# ms32c000axx register map
Vendor: MS; Series: MS32C; File version: 1.0.0
CPU: CM0+ r0p1, little endian, no MPU, no FPU, 4 interrupt priority bits
Registers are 32-bit, read-write, reset 0x0 unless marked. A register's access mark holds for its fields unless they carry their own. Offsets are from the block's base; [hi:lo] are bit positions; {n}, {i} and the like mark numbered series.

## PWR — Power control
Base 0x40007000
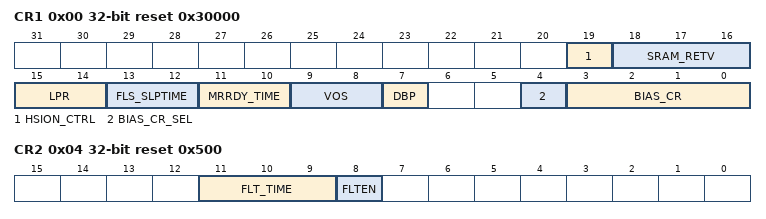
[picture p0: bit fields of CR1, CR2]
0x00 CR1 reset 0x30000 — Power control register 1
  [19] HSION_CTRL — HSI open time control
  [18:16] SRAM_RETV — SRAM retention voltage control
  [15:14] LPR — Low-power run
  [13:12] FLS_SLPTIME — Flash wait time after wakeup from the stop mode
  [11:10] MRRDY_TIME — Time selection wakeup from LP to VR
  [9:8] VOS — Voltage scaling range selection
  [7] DBP — Disable backup domain write protection
  [4] BIAS_CR_SEL — MR Bias current selection
  [3:0] BIAS_CR — MR Bias current
0x04 CR2 reset 0x500 — Power control register 2
  [11:9] FLT_TIME — Digital filter time configuration
  [8] FLTEN — Digital filter enable

## RCC — Reset and clock control
Base 0x40021000
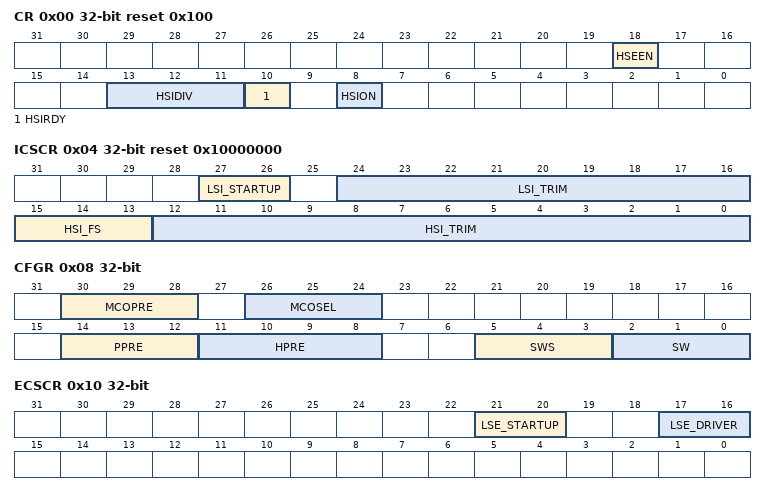
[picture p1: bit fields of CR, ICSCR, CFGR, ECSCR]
0x00 CR reset 0x100 — Clock control register
  [18] HSEEN
  [13:11] HSIDIV — HSI16 clock division factor
  [10] HSIRDY — HSI16 clock ready flag
  [8] HSION — HSI16 clock enable
0x04 ICSCR reset 0x10000000 — Internal clock sources calibration register
  [27:26] LSI_STARTUP — LSI startup time
  [24:16] LSI_TRIM — LSI clock trimming
  [15:13] HSI_FS — HSI frequency selection
  [12:0] HSI_TRIM — HSI clock trimming
0x08 CFGR — Clock configuration register
  [30:28] MCOPRE — Microcontroller clock output prescaler
  [26:24] MCOSEL — Microcontroller clock output
  [14:12] PPRE — APB prescaler
  [11:8] HPRE — AHB prescaler
  [5:3] SWS ro — System clock switch status
  [2:0] SW — System clock switch
0x10 ECSCR — External clock source control register
  [21:20] LSE_STARTUP, [17:16] LSE_DRIVER
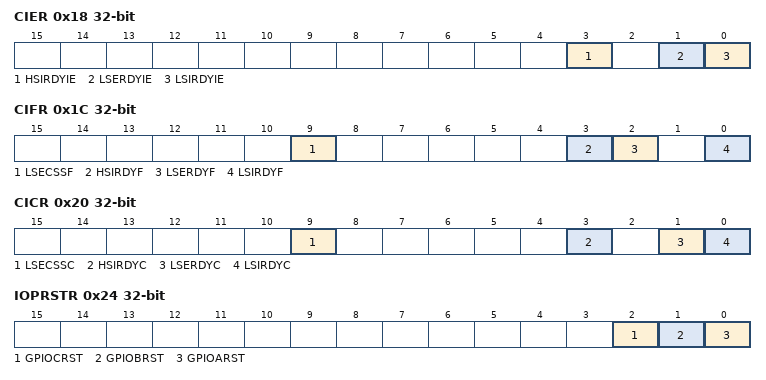
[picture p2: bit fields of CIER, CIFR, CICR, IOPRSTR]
0x18 CIER — Clock interrupt enable register
  [3] HSIRDYIE — HSI ready interrupt enable
  [1] LSERDYIE — LSE ready interrupt enable
  [0] LSIRDYIE — LSI ready interrupt enable
0x1C CIFR ro — Clock interrupt flag register
  [9] LSECSSF — LSE clock secure system interrupt flag
  [3] HSIRDYF — HSI ready interrupt flag
  [2] LSERDYF — LSE ready interrupt flag
  [0] LSIRDYF — LSI ready interrupt flag
0x20 CICR wo — Clock interrupt clear register
  [9] LSECSSC — LSE clock secure system interrupt flag clear
  [3] HSIRDYC — HSI ready interrupt clear
  [1] LSERDYC — LSE ready interrupt clear
  [0] LSIRDYC — LSI ready interrupt clear
0x24 IOPRSTR — GPIO reset register
  [2] GPIOCRST — I/O port C reset
  [1] GPIOBRST — I/O port B reset
  [0] GPIOARST — I/O port A reset
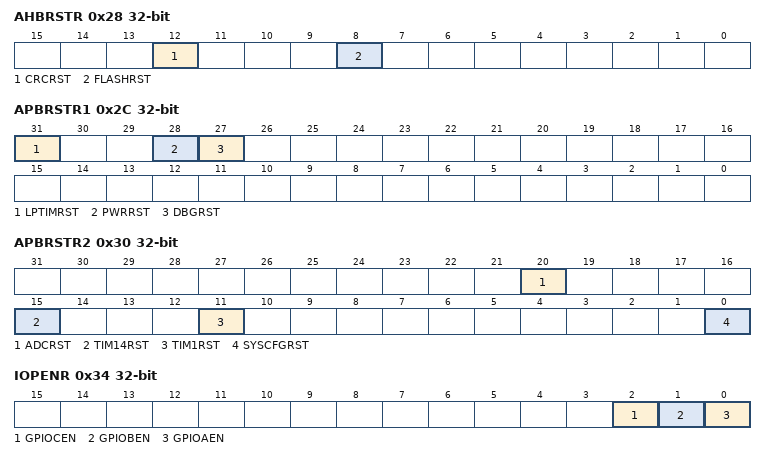
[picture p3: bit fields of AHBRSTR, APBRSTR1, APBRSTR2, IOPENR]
0x28 AHBRSTR — AHB peripheral reset register
  [12] CRCRST — CRC reset
  [8] FLASHRST — FLASH reset
0x2C APBRSTR1 — APB peripheral reset register 1
  [31] LPTIMRST — Low Power Timer reset
  [28] PWRRST — Power interface reset
  [27] DBGRST — Debug support reset
0x30 APBRSTR2 — APB peripheral reset register 2
  [20] ADCRST — ADC reset
  [15] TIM14RST — TIM14 reset
  [11] TIM1RST — TIM1 timer reset
  [0] SYSCFGRST — SYSCFG reset
0x34 IOPENR — GPIO clock enable register
  [2] GPIOCEN — I/O port C clock enable
  [1] GPIOBEN — I/O port B clock enable
  [0] GPIOAEN — I/O port A clock enable
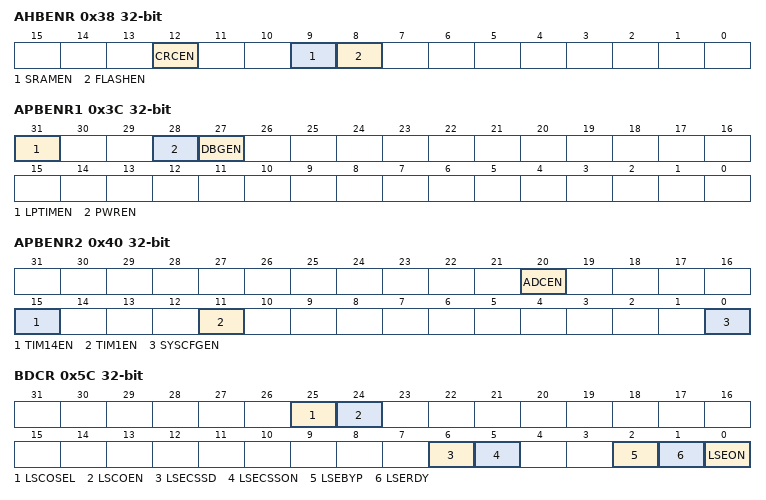
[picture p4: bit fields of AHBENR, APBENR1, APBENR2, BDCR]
0x38 AHBENR — AHB peripheral clock enable register
  [12] CRCEN — CRC clock enable
  [9] SRAMEN — SRAM memory interface clock enable
  [8] FLASHEN — Flash memory interface clock enable
0x3C APBENR1 — APB peripheral clock enable register 1
  [31] LPTIMEN — LPTIM clock enable
  [28] PWREN — Power interface clock enable
  [27] DBGEN — Debug support clock enable
0x40 APBENR2 — APB peripheral clock enable register 2
  [20] ADCEN — ADC clock enable
  [15] TIM14EN — TIM14 clock enable
  [11] TIM1EN — TIM1 timer clock enable
  [0] SYSCFGEN — SYSCFG and VREFBUF clock enable
0x54 CCIPR — Peripherals independent clock configuration register
  [19:18] LPTIM1SEL — LPTIM1 clock source selection
0x5C BDCR — RTC domain control register
  [25] LSCOSEL — Low-speed clock output selection
  [24] LSCOEN — Low-speed clock output (LSCO) enable
  [6] LSECSSD — LSE CSS detect
  [5] LSECSSON — LSE CSS enable
  [2] LSEBYP — LSE oscillator bypass
  [1] LSERDY — LSE oscillator ready
  [0] LSEON — LSE oscillator enable
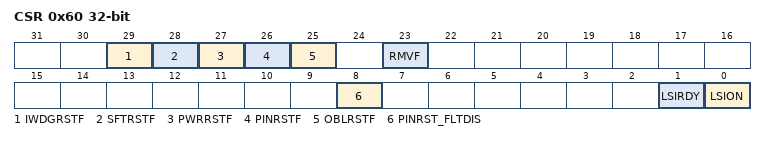
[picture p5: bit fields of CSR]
0x60 CSR — Control/status register
  [29] IWDGRSTF — Independent window watchdog reset flag
  [28] SFTRSTF — Software reset flag
  [27] PWRRSTF — BOR or POR/PDR flag
  [26] PINRSTF — Pin reset flag
  [25] OBLRSTF — Option byte loader reset flag
  [23] RMVF — Remove reset flags
  [8] PINRST_FLTDIS
  [1] LSIRDY — LSI oscillator ready
  [0] LSION — LSI oscillator enable

## SYSCFG — System configuration controller
Base 0x40010000
0x00 CFGR1 — SYSCFG configuration register 1
  [1:0] MEM_MODE — Memory mapping selection bits
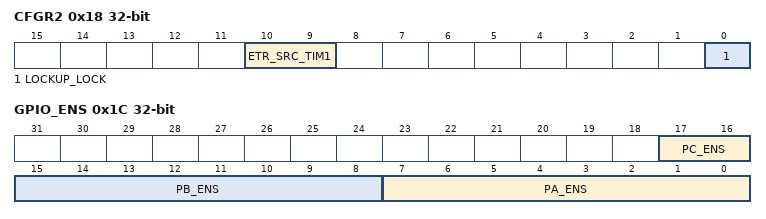
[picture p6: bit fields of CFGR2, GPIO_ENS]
0x18 CFGR2 — SYSCFG configuration register 2
  [10:9] ETR_SRC_TIM1 — TIM1 ETR source selection
  [0] LOCKUP_LOCK — Cortex-M0+ LOCKUP bit enable bit
0x1C GPIO_ENS
  [17:16] PC_ENS, [15:8] PB_ENS, [7:0] PA_ENS

## TIM1 — Advanced timer
Base 0x40012C00
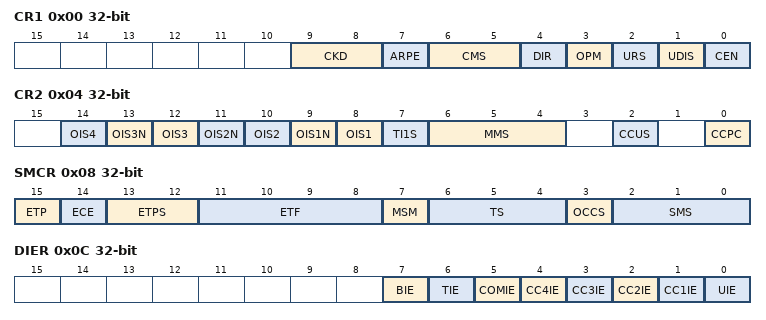
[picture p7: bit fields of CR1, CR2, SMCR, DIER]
0x00 CR1
  [9:8] CKD, [7] ARPE, [6:5] CMS, [4] DIR, [3] OPM, [2] URS, [1] UDIS, [0] CEN
0x04 CR2 (reset mask 0xF8)
  [2n+6] OIS{n} (n=1..4), [13] OIS3N, [11] OIS2N, [9] OIS1N, [7] TI1S, [6:4] MMS, [2] CCUS, [0] CCPC
0x08 SMCR (reset mask 0xFFF7)
  [15] ETP, [14] ECE, [13:12] ETPS, [11:8] ETF, [7] MSM, [6:4] TS, [3] OCCS, [2:0] SMS
0x0C DIER (reset mask 0x5F5F)
  [7] BIE, [6] TIE, [5] COMIE, [n] CC{n}IE (n=1..4), [0] UIE
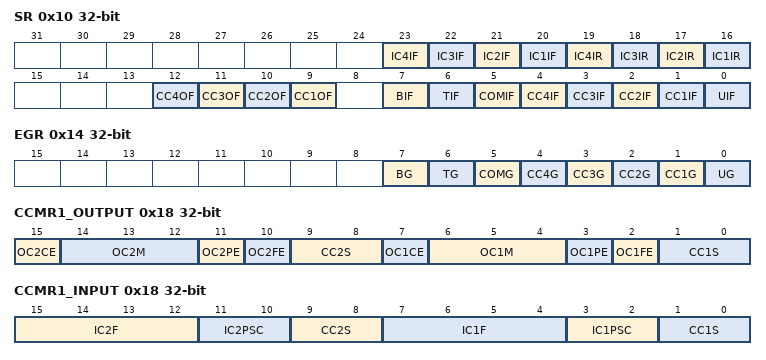
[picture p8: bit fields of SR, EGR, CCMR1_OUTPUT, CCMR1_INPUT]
0x10 SR (reset mask 0x1E5F)
  [23] IC4IF — desc IC3IF
  [22] IC3IF
  [21] IC2IF
  [20] IC1IF
  [19] IC4IR — desc IC3IR
  [18] IC3IR
  [17] IC2IR
  [16] IC1IR
  [n+8] CC{n}OF (n=1..4)
  [7] BIF
  [6] TIF
  [5] COMIF
  [n] CC{n}IF (n=1..4)
  [0] UIF
0x14 EGR wo (reset mask 0x5F)
  [7] BG
  [6] TG
  [5] COMG
  [4] CC4G
  [3] CC3G
  [2] CC2G
  [1] CC1G — Capture 1 Generation
  [0] UG
0x18 CCMR1_OUTPUT
  [15] OC2CE, [14:12] OC2M, [11] OC2PE, [10] OC2FE, [9:8] CC2S, [7] OC1CE, [6:4] OC1M, [3] OC1PE, [2] OC1FE, [1:0] CC1S
0x18 CCMR1_INPUT (alternate view of CCMR1_OUTPUT)
  [15:12] IC2F, [11:10] IC2PSC, [9:8] CC2S, [7:4] IC1F, [3:2] IC1PSC, [1:0] CC1S
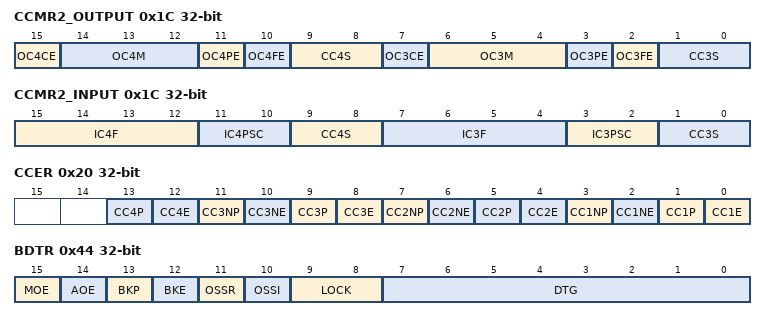
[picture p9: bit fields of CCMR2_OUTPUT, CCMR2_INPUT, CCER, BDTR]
0x1C CCMR2_OUTPUT
  [15] OC4CE, [14:12] OC4M, [11] OC4PE, [10] OC4FE, [9:8] CC4S, [7] OC3CE, [6:4] OC3M, [3] OC3PE, [2] OC3FE, [1:0] CC3S
0x1C CCMR2_INPUT (alternate view of CCMR2_OUTPUT)
  [15:12] IC4F, [11:10] IC4PSC, [9:8] CC4S, [7:4] IC3F, [3:2] IC3PSC, [1:0] CC3S
0x20 CCER (reset mask 0x3333)
  [4n-3] CC{n}P (n=1..4), [4n-4] CC{n}E (n=1..4), [11] CC3NP, [10] CC3NE, [7] CC2NP, [6] CC2NE, [3] CC1NP, [2] CC1NE
0x24 CNT
  [15:0] CNT
0x28 PSC
  [15:0] PSC
0x2C ARR reset 0xFFFF
  [15:0] ARR
0x30 RCR reset 0xFFFF
  [7:0] REP
{0x30+4i} CCR{i} (i=1..4)
  [15:0] CCR{i}
0x44 BDTR
  [15] MOE, [14] AOE, [13] BKP, [12] BKE, [11] OSSR, [10] OSSI, [9:8] LOCK, [7:0] DTG

## TIM14 — General purpose timer
Base 0x40002000
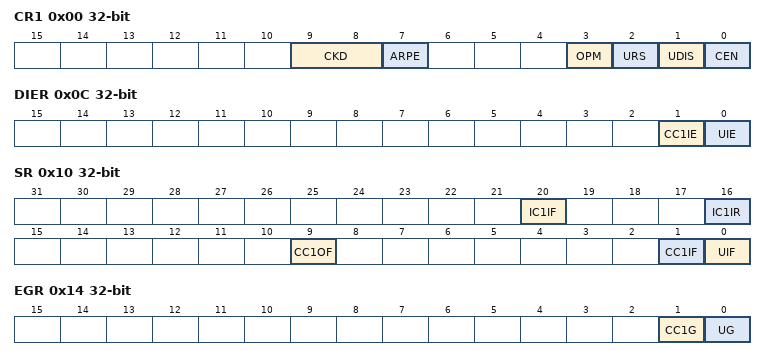
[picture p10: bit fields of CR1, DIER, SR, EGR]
0x00 CR1
  [9:8] CKD, [7] ARPE, [3] OPM, [2] URS, [1] UDIS, [0] CEN
0x0C DIER
  [1] CC1IE, [0] UIE
0x10 SR (reset mask 0x1E5F)
  [20] IC1IF, [16] IC1IR, [9] CC1OF, [1] CC1IF, [0] UIF
0x14 EGR wo
  [1] CC1G — Capture Generation
  [0] UG
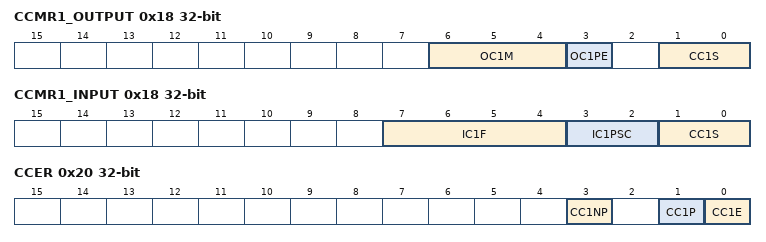
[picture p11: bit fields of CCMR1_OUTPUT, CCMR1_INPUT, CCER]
0x18 CCMR1_OUTPUT
  [6:4] OC1M, [3] OC1PE, [1:0] CC1S
0x18 CCMR1_INPUT (alternate view of CCMR1_OUTPUT)
  [7:4] IC1F, [3:2] IC1PSC, [1:0] CC1S
0x20 CCER (reset mask 0x3333)
  [3] CC1NP, [1] CC1P, [0] CC1E
0x24 CNT
  [15:0] CNT
0x28 PSC
  [15:0] PSC
0x2C ARR reset 0xFFFF
  [15:0] ARR
0x34 CCR1
  [15:0] CCR1
0x50 OR
  [1:0] TI1_RMP
